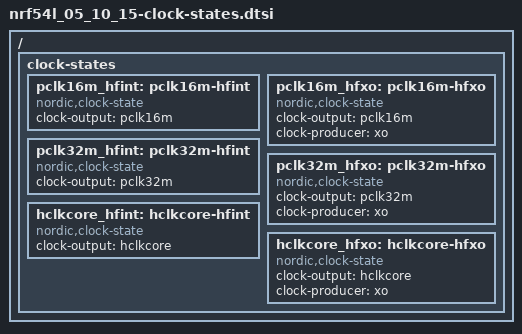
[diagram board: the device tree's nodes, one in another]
/*
 * Copyright (c) 2026 Nordic Semiconductor ASA
 *
 * SPDX-License-Identifier: Apache-2.0
 */

/* Clock states of the nRF54L05/10/15 clocks. Each state is a pure descriptor selected by a
 * consumer's `clocks` property; it is /omit-if-no-ref/ so it costs nothing until referenced.
 * Included at the end of the SoC devicetree, after the referenced signals and producers.
 */

/ {
	clock-states {
		/* States of the 16 MHz peripheral clock. Both run the peripheral at the same
		 * frequency; they differ in whether the HFXO is requested, which trades
		 * startup latency for bitrate accuracy.
		 */
		/omit-if-no-ref/ pclk16m_hfint: pclk16m-hfint {
			compatible = "nordic,clock-state";
			#clock-cells = <0>;
			clock-output = <&pclk16m>;
		};

		/omit-if-no-ref/ pclk16m_hfxo: pclk16m-hfxo {
			compatible = "nordic,clock-state";
			#clock-cells = <0>;
			clock-output = <&pclk16m>;
			clock-producer = <&xo>;
		};

		/* States of the 32 MHz peripheral clock (for example I2S). Same frequency in both;
		 * they differ in whether the HFXO is requested for accuracy.
		 */
		/omit-if-no-ref/ pclk32m_hfint: pclk32m-hfint {
			compatible = "nordic,clock-state";
			#clock-cells = <0>;
			clock-output = <&pclk32m>;
		};

		/omit-if-no-ref/ pclk32m_hfxo: pclk32m-hfxo {
			compatible = "nordic,clock-state";
			#clock-cells = <0>;
			clock-output = <&pclk32m>;
			clock-producer = <&xo>;
		};

		/* States of the core high-frequency clock. Same frequency in both; they differ in
		 * whether the HFXO is requested for accuracy.
		 */
		/omit-if-no-ref/ hclkcore_hfint: hclkcore-hfint {
			compatible = "nordic,clock-state";
			#clock-cells = <0>;
			clock-output = <&hclkcore>;
		};

		/omit-if-no-ref/ hclkcore_hfxo: hclkcore-hfxo {
			compatible = "nordic,clock-state";
			#clock-cells = <0>;
			clock-output = <&hclkcore>;
			clock-producer = <&xo>;
		};
	};
};
